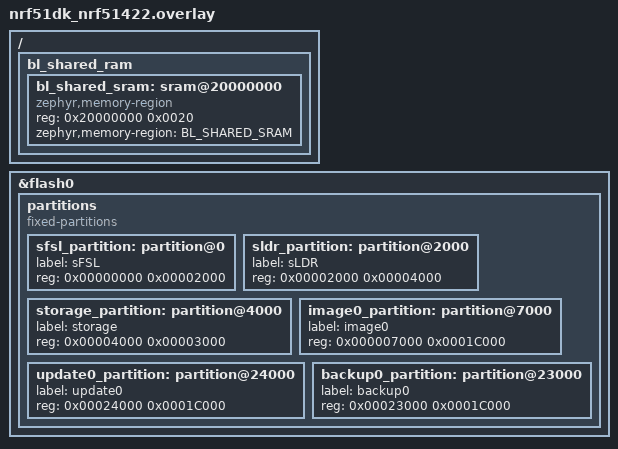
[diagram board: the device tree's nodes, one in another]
/*
 * Copyright (c) 2022 Laczen
 *
 * SPDX-License-Identifier: Apache-2.0
 */

#include "../app.overlay"

/delete-node/ &boot_partition;
/delete-node/ &slot0_partition;
/delete-node/ &slot1_partition;
/delete-node/ &storage_partition;

&flash0 {
	partitions {
		compatible = "fixed-partitions";
		#address-cells = <1>;
		#size-cells = <1>;

		sfsl_partition: partition@0 {
			label = "sFSL";
			reg = <0x00000000 0x00002000>;
		};

		sldr_partition: partition@2000 {
			label = "sLDR";
			reg = <0x00002000 0x00004000>;
		};

		storage_partition: partition@4000 {
			label = "storage";
			reg = <0x00004000 0x00003000>;
		};

		image0_partition: partition@7000 {
			label = "image0";
			reg = <0x000007000 0x0001C000>;
		};

		update0_partition: partition@24000 {
			label = "update0";
			reg = <0x00024000 0x0001C000>;
		};

		backup0_partition: partition@23000 {
			label = "backup0";
			reg = <0x00023000 0x0001C000>;
		};

	};
};

/ {
	bl_shared_ram {
		#address-cells = < 0x1 >;
		#size-cells = < 0x1 >;

		bl_shared_sram: sram@20000000 {
			compatible = "zephyr,memory-region", "mmio-sram";
			reg = < 0x20000000 0x0020 >;
			zephyr,memory-region = "BL_SHARED_SRAM";
		};
	};
};
